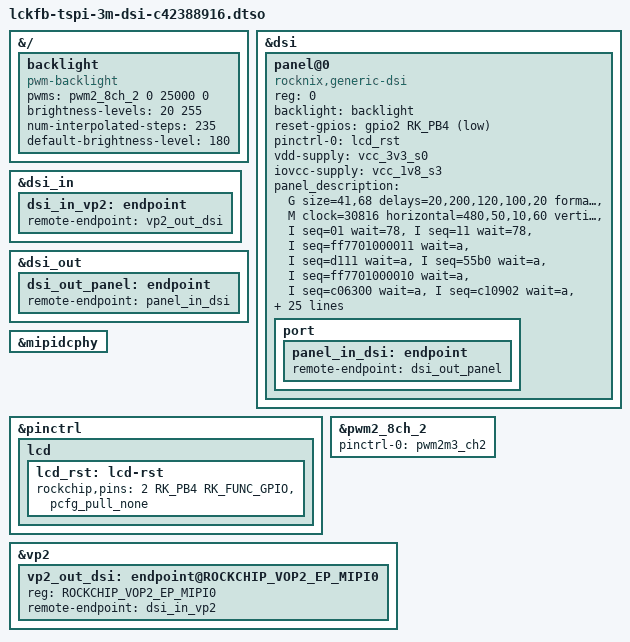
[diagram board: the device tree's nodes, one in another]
// SPDX-License-Identifier: (GPL-2.0+ OR MIT)
/*
 * LCKFB TaishanPi 3M: 3.1 inch 480x800 MIPI DSI screen (LCSC C42388916)
 *
 * Panel timings and init sequence are from LCKFB's vendor kernel device
 * tree, in the form the rocknix,generic-dsi driver takes.
 *
 * Not tested on hardware: converted from the vendor data. Display and
 * backlight only; the CST128 touch controller has no driver enabled here.
 */

/dts-v1/;
/plugin/;

#include <dt-bindings/gpio/gpio.h>
#include <dt-bindings/pinctrl/rockchip.h>
#include <dt-bindings/soc/rockchip,vop2.h>

&{/} {
	backlight: backlight {
		compatible = "pwm-backlight";
		pwms = <&pwm2_8ch_2 0 25000 0>;
		brightness-levels = <20 255>;
		num-interpolated-steps = <235>;
		default-brightness-level = <180>;
	};
};

&dsi {
	#address-cells = <1>;
	#size-cells = <0>;
	status = "okay";

	panel@0 {
		compatible = "rocknix,generic-dsi";
		reg = <0>;
		backlight = <&backlight>;
		reset-gpios = <&gpio2 RK_PB4 GPIO_ACTIVE_LOW>;
		pinctrl-names = "default";
		pinctrl-0 = <&lcd_rst>;
		vdd-supply = <&vcc_3v3_s0>;
		iovcc-supply = <&vcc_1v8_s3>;

		panel_description =
			"G size=41,68 delays=20,200,120,100,20 format=rgb888 lanes=2 flags=0x803",
			"M clock=30816 horizontal=480,50,10,60 vertical=800,20,2,34 default=1",
			"I seq=01 wait=78",
			"I seq=11 wait=78",
			"I seq=ff7701000011 wait=a",
			"I seq=d111 wait=a",
			"I seq=55b0 wait=a",
			"I seq=ff7701000010 wait=a",
			"I seq=c06300 wait=a",
			"I seq=c10902 wait=a",
			"I seq=c23708 wait=a",
			"I seq=c700 wait=a",
			"I seq=cc38 wait=a",
			"I seq=b00011190c1006070a092204100e28301c wait=a",
			"I seq=b10012190d10040607082304121128301c wait=6e",
			"I seq=ff7701000011 wait=a",
			"I seq=b04d wait=a",
			"I seq=b160 wait=a",
			"I seq=b207 wait=a",
			"I seq=b380 wait=6e",
			"I seq=b547 wait=a",
			"I seq=b78a wait=a",
			"I seq=b821 wait=a",
			"I seq=c178 wait=a",
			"I seq=c278 wait=a",
			"I seq=d088 wait=a",
			"I seq=e0000002 wait=a",
			"I seq=e101a003a002a004a0004444 wait=a",
			"I seq=e2000000000000000000000000 wait=a",
			"I seq=e300003333 wait=a",
			"I seq=e44444 wait=a",
			"I seq=e50126a0a00328a0a0052aa0a0072ca0a0 wait=a",
			"I seq=e600003333 wait=a",
			"I seq=e74444 wait=a",
			"I seq=e80226a0a00428a0a0062aa0a0082ca0a0 wait=a",
			"I seq=eb0001e4e4440040 wait=a",
			"I seq=edfff7654f0ba1cffffffc1ab0f4567fff wait=a",
			"I seq=ee42 wait=a",
			"I seq=ff7701000000 wait=a",
			"I seq=3600 wait=a",
			"I seq=3a55 wait=a",
			"I seq=11 wait=78",
			"I seq=29 wait=14";

		port {
			panel_in_dsi: endpoint {
				remote-endpoint = <&dsi_out_panel>;
			};
		};
	};
};

&dsi_in {
	dsi_in_vp2: endpoint {
		remote-endpoint = <&vp2_out_dsi>;
	};
};

&dsi_out {
	dsi_out_panel: endpoint {
		remote-endpoint = <&panel_in_dsi>;
	};
};

&mipidcphy {
	status = "okay";
};

&pinctrl {
	lcd {
		lcd_rst: lcd-rst {
			rockchip,pins = <2 RK_PB4 RK_FUNC_GPIO &pcfg_pull_none>;
		};
	};

};

&pwm2_8ch_2 {
	pinctrl-names = "default";
	pinctrl-0 = <&pwm2m3_ch2>;
	status = "okay";
};

&vp2 {
	#address-cells = <1>;
	#size-cells = <0>;

	vp2_out_dsi: endpoint@ROCKCHIP_VOP2_EP_MIPI0 {
		reg = <ROCKCHIP_VOP2_EP_MIPI0>;
		remote-endpoint = <&dsi_in_vp2>;
	};
};
